# ESP32S31_RADIO register map
Vendor: Espressif; Series: ESP32-S31; File version: 3.52
Registers are 32-bit, read-write, no defined reset value unless marked. A register's access mark holds for its fields unless they carry their own. Offsets are from the block's base; [hi:lo] are bit positions.

## WIFI_MAC_INTERNAL_TX_BLOCK_ACK — Complete dbg_read_internal_txba reads one internal WDEVTXBA result: a 64-bit bitmap, two transmitter-address words and a combined fragment/starting-sequence/TID word.
Base 0x2010429C
0x00 BITMAP_HIGH ro — Project-assigned name.
  [31:0] BITMAP — Project-assigned name. High 32 bits of the internal transmit BlockAck acknowledgement bitmap.
0x04 BITMAP_LOW ro — Project-assigned name.
  [31:0] BITMAP — Project-assigned name. Low 32 bits of the internal transmit BlockAck acknowledgement bitmap.
0x08 TRANSMITTER_ADDRESS_WORD_0 ro — Project-assigned name. First WDEVTXBA TA word printed by the complete blob decoder. Byte ordering is retained as a raw word until a matching live frame qualifies it.
0x0C TRANSMITTER_ADDRESS_WORD_1 ro — Project-assigned name. Second WDEVTXBA TA word printed by the complete blob decoder. Byte ordering is retained as a raw word until a matching live frame qualifies it.
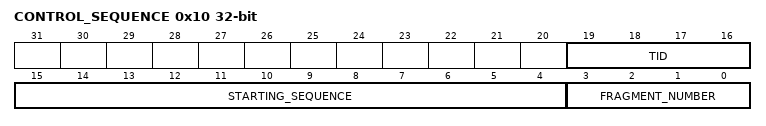
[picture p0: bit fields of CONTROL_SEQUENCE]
0x10 CONTROL_SEQUENCE ro — Project-assigned name.
  [19:16] TID — Project-assigned name.
  [15:4] STARTING_SEQUENCE — Project-assigned name.
  [3:0] FRAGMENT_NUMBER — Project-assigned name.

## WIFI_MAC_HE_COLOR_COLLISION — Complete dbg_read_color_collision reads the 64-bit observed BSS-color bitmap. Its adjacent control word is the canonical WIFI_MAC_HE_INIT_PREFIX.RX_FIELD_CONTROL register. Open HE HIL observed color bit 25, threshold one and timeout 60 seconds.
Base 0x20104040
0x00 BSS_COLOR_BITMAP_LOW ro — Project-assigned name. RX_HE_BSS_COLOR_MAPLO.
  [31:0] VALUE — Project-assigned name.
0x04 BSS_COLOR_BITMAP_HIGH ro — Project-assigned name. RX_HE_BSS_COLOR_MAPHI.
  [31:0] VALUE — Project-assigned name.

## WIFI_MAC_RX_POWER_SAVE — WDEV_RX_POWER_SAVE_CONF decoded by complete dbg_read_rx_misc. Complete hal_he_set_power_save sets the interface-zero intra-PPDU and BSS-color-check bits as the tail of hal_he_bssid_init; open associated-STA HIL read both bits set.
Base 0x201040A0
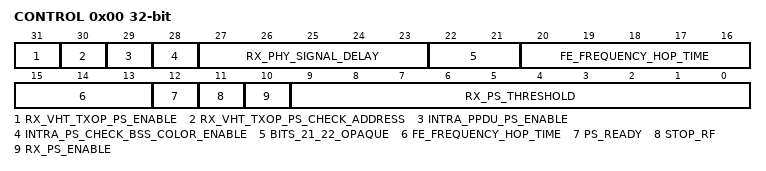
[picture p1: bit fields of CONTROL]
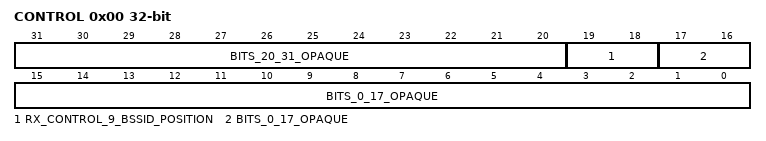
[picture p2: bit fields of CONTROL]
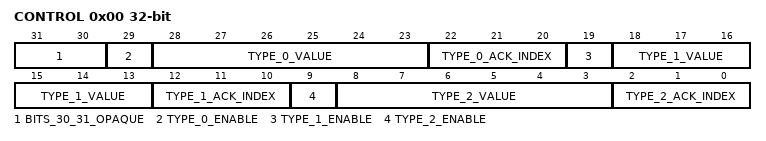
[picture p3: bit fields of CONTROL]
0x00 CONTROL — Project-assigned name.
  [31] RX_VHT_TXOP_PS_ENABLE — Project-assigned name.
  [30] RX_VHT_TXOP_PS_CHECK_ADDRESS — Project-assigned name.
  [29] INTRA_PPDU_PS_ENABLE — Project-assigned name. Complete hal_he_set_power_save sets bit 29 for interface zero immediately before bit 28; dbg_read_rx_misc names it INTRA_PPDU_PS.
  [28] INTRA_PS_CHECK_BSS_COLOR_ENABLE — Project-assigned name. Complete hal_he_set_power_save sets bit 28 for interface zero as the final fresh-read RMW of hal_he_bssid_init; dbg_read_rx_misc names it INTRA_PS_CHECK_BSS_COLOR.
  [27:23] RX_PHY_SIGNAL_DELAY — Project-assigned name.
  [22:21] BITS_21_22_OPAQUE — Opaque: meaning not established.
  [20:13] FE_FREQUENCY_HOP_TIME — Project-assigned name.
  [12] PS_READY — Project-assigned name.
  [11] STOP_RF — Project-assigned name.
  [10] RX_PS_ENABLE — Project-assigned name.
  [9:0] RX_PS_THRESHOLD — Project-assigned name.

## WIFI_MAC_RX_BSSID_LIST — Canonical WDEVRXCTR_BSSIDLIST word. Complete dbg_read_rx_misc names bits 19:18 RXCTL9_BSSID_POS; the HE init prefix independently writes encoding two to that same field.
Base 0x20104110
0x00 CONTROL — Project-assigned name.
  [31:20] BITS_20_31_OPAQUE — Opaque: meaning not established.
  [19:18] RX_CONTROL_9_BSSID_POSITION — Project-assigned name. Debug-decoded BSSID position field; complete hal_he_init writes encoding two.
  [17:0] BITS_0_17_OPAQUE — Opaque: meaning not established.

## WIFI_MAC_RX_CUSTOM_TYPE — WDEVTXRX_TAB three custom frame-type match and ACK-index profiles decoded by complete dbg_read_rx_misc.
Base 0x20104CA4
0x00 CONTROL — Project-assigned name.
  [31:30] BITS_30_31_OPAQUE — Opaque: meaning not established.
  [29] TYPE_0_ENABLE — Project-assigned name.
  [28:23] TYPE_0_VALUE — Project-assigned name.
  [22:20] TYPE_0_ACK_INDEX — Project-assigned name.
  [19] TYPE_1_ENABLE — Project-assigned name.
  [18:13] TYPE_1_VALUE — Project-assigned name.
  [12:10] TYPE_1_ACK_INDEX — Project-assigned name.
  [9] TYPE_2_ENABLE — Project-assigned name.
  [8:3] TYPE_2_VALUE — Project-assigned name.
  [2:0] TYPE_2_ACK_INDEX — Project-assigned name.
